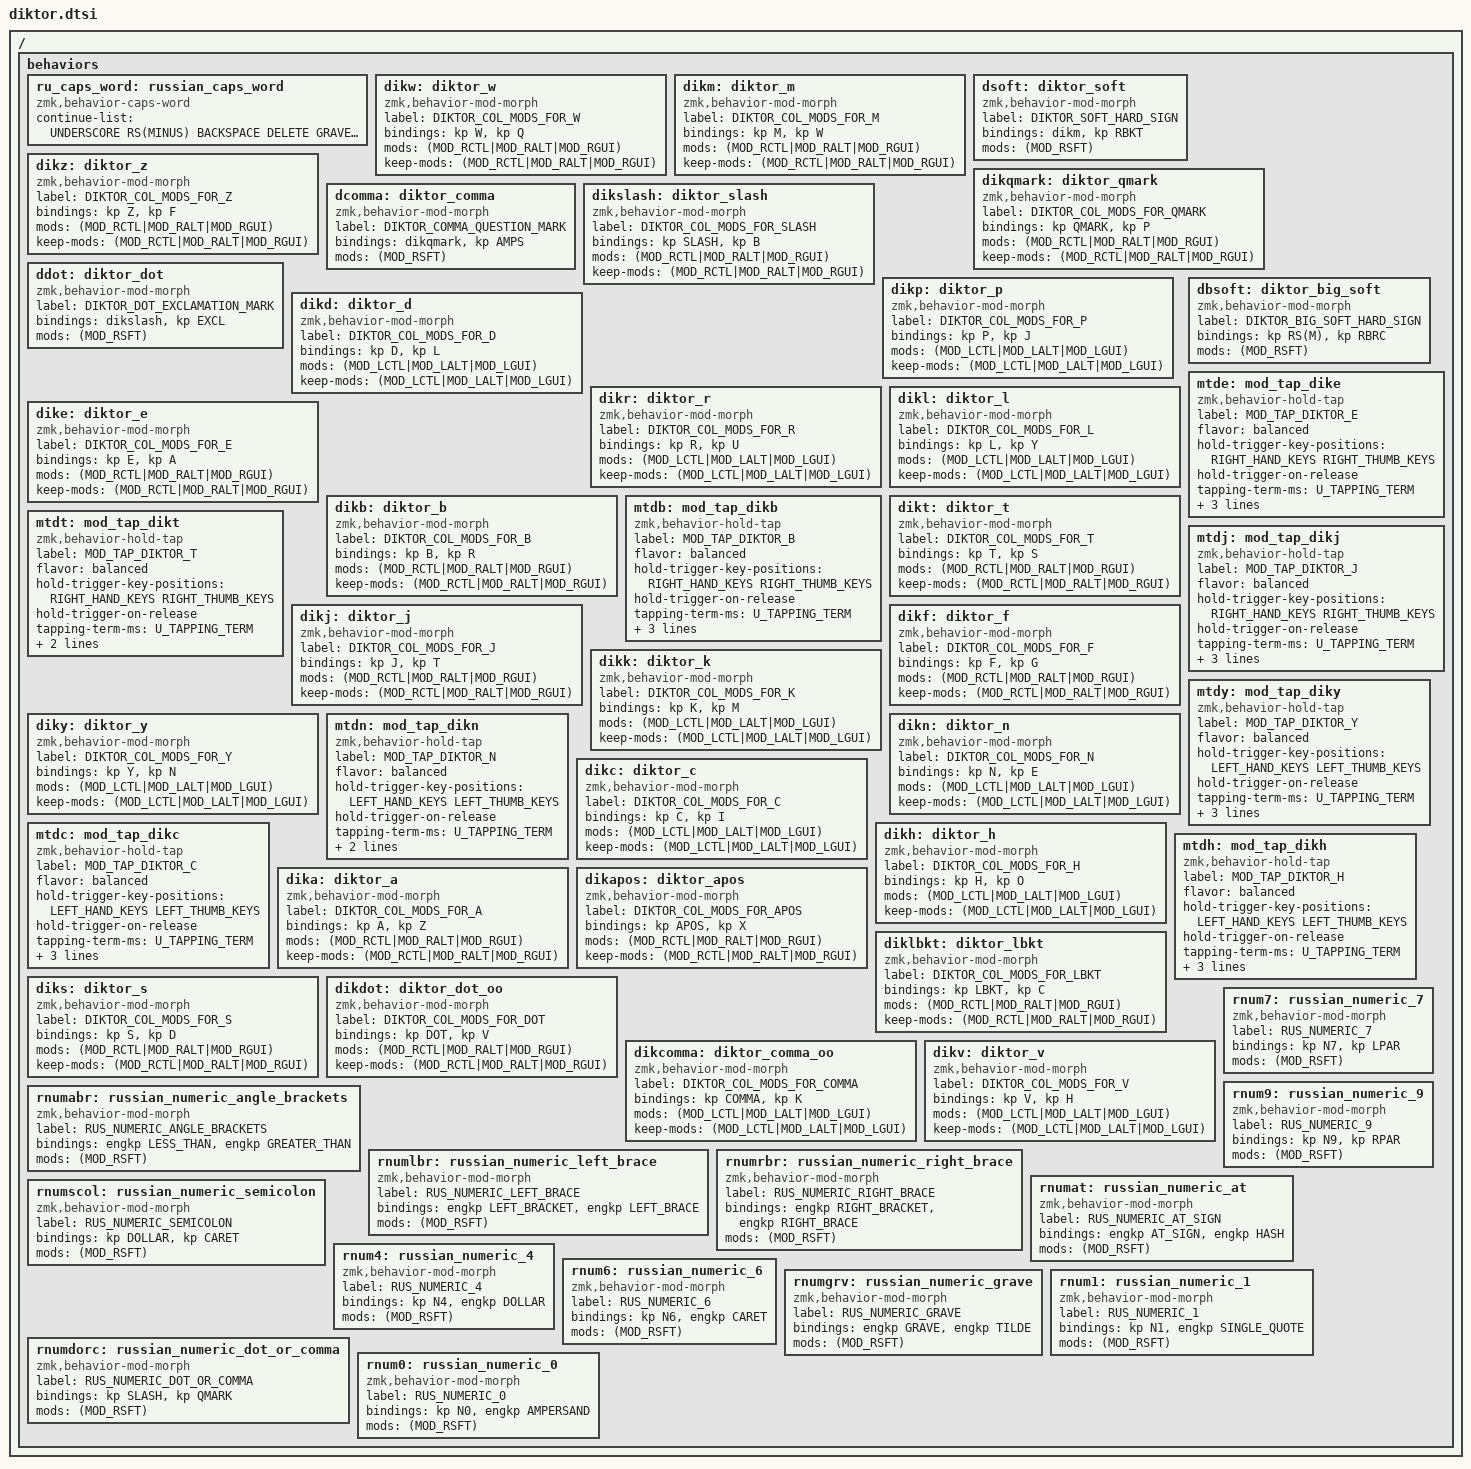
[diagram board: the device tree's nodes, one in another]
// Diktor layout behaviors

/ {
    behaviors {
        // Russian layer
        ru_caps_word: russian_caps_word {
            // behavior-caps-word is useless for Russian as it doesn't shift chars outside of a-z
            // loking forward to PR#2043's &capslock_word
            compatible = "zmk,behavior-caps-word";
            #binding-cells = <0>;
            continue-list = <UNDERSCORE RS(MINUS) BACKSPACE DELETE GRAVE LBKT RBKT APOS DOT COMMA SEMI>;
        };
        //  Ц >> Q
        dikw: diktor_w {
            compatible = "zmk,behavior-mod-morph";
            label = "DIKTOR_COL_MODS_FOR_W";
            #binding-cells = <0>;
            bindings = <&kp W>, <&kp Q>;
            mods = <(MOD_RCTL|MOD_RALT|MOD_RGUI)>;
            keep-mods = <(MOD_RCTL|MOD_RALT|MOD_RGUI)>;
        };
        //  ь/ъ >> W
        dikm: diktor_m {
            compatible = "zmk,behavior-mod-morph";
            label = "DIKTOR_COL_MODS_FOR_M";
            #binding-cells = <0>;
            bindings = <&kp M>, <&kp W>;
            mods = <(MOD_RCTL|MOD_RALT|MOD_RGUI)>;
            keep-mods = <(MOD_RCTL|MOD_RALT|MOD_RGUI)>;
        };
        dsoft: diktor_soft {
            compatible = "zmk,behavior-mod-morph";
            label = "DIKTOR_SOFT_HARD_SIGN";
            #binding-cells = <0>;
            bindings = <&dikm>, <&kp RBKT>;
            mods = <(MOD_RSFT)>;
        };
        //  Я >> F
        dikz: diktor_z {
            compatible = "zmk,behavior-mod-morph";
            label = "DIKTOR_COL_MODS_FOR_Z";
            #binding-cells = <0>;
            bindings = <&kp Z>, <&kp F>;
            mods = <(MOD_RCTL|MOD_RALT|MOD_RGUI)>;
            keep-mods = <(MOD_RCTL|MOD_RALT|MOD_RGUI)>;
        };
        //  ,/? >> P
        dikqmark: diktor_qmark {
            compatible = "zmk,behavior-mod-morph";
            label = "DIKTOR_COL_MODS_FOR_QMARK";
            #binding-cells = <0>;
            bindings = <&kp QMARK>, <&kp P>;
            mods = <(MOD_RCTL|MOD_RALT|MOD_RGUI)>;
            keep-mods = <(MOD_RCTL|MOD_RALT|MOD_RGUI)>;
        };
        dcomma: diktor_comma {
            compatible = "zmk,behavior-mod-morph";
            label = "DIKTOR_COMMA_QUESTION_MARK";
            #binding-cells = <0>;
            bindings = <&dikqmark>, <&kp AMPS>;
            mods = <(MOD_RSFT)>;
        };
        //  ./! >> B
        dikslash: diktor_slash {
            compatible = "zmk,behavior-mod-morph";
            label = "DIKTOR_COL_MODS_FOR_SLASH";
            #binding-cells = <0>;
            bindings = <&kp SLASH>, <&kp B>;
            mods = <(MOD_RCTL|MOD_RALT|MOD_RGUI)>;
            keep-mods = <(MOD_RCTL|MOD_RALT|MOD_RGUI)>;
        };
        ddot: diktor_dot {
            compatible = "zmk,behavior-mod-morph";
            label = "DIKTOR_DOT_EXCLAMATION_MARK";
            #binding-cells = <0>;
            bindings = <&dikslash>, <&kp EXCL>;
            mods = <(MOD_RSFT)>;
        };
        //  З >> J
        dikp: diktor_p {
            compatible = "zmk,behavior-mod-morph";
            label = "DIKTOR_COL_MODS_FOR_P";
            #binding-cells = <0>;
            bindings = <&kp P>, <&kp J>;
            mods = <(MOD_LCTL|MOD_LALT|MOD_LGUI)>;
            keep-mods = <(MOD_LCTL|MOD_LALT|MOD_LGUI)>;
        };
        //  В >> L
        dikd: diktor_d {
            compatible = "zmk,behavior-mod-morph";
            label = "DIKTOR_COL_MODS_FOR_D";
            #binding-cells = <0>;
            bindings = <&kp D>, <&kp L>;
            mods = <(MOD_LCTL|MOD_LALT|MOD_LGUI)>;
            keep-mods = <(MOD_LCTL|MOD_LALT|MOD_LGUI)>;
        };
        //  К >> U
        dikr: diktor_r {
            compatible = "zmk,behavior-mod-morph";
            label = "DIKTOR_COL_MODS_FOR_R";
            #binding-cells = <0>;
            bindings = <&kp R>, <&kp U>;
            mods = <(MOD_LCTL|MOD_LALT|MOD_LGUI)>;
            keep-mods = <(MOD_LCTL|MOD_LALT|MOD_LGUI)>;
        };
        //  Д >> Y
        dikl: diktor_l {
            compatible = "zmk,behavior-mod-morph";
            label = "DIKTOR_COL_MODS_FOR_L";
            #binding-cells = <0>;
            bindings = <&kp L>, <&kp Y>;
            mods = <(MOD_LCTL|MOD_LALT|MOD_LGUI)>;
            keep-mods = <(MOD_LCTL|MOD_LALT|MOD_LGUI)>;
        };
        //  Ь/Ъ
        dbsoft: diktor_big_soft {
            compatible = "zmk,behavior-mod-morph";
            label = "DIKTOR_BIG_SOFT_HARD_SIGN";
            #binding-cells = <0>;
            bindings = <&kp RS(M)>, <&kp RBRC>;
            mods = <(MOD_RSFT)>;
        };
        //  У >> A
        dike: diktor_e {
            compatible = "zmk,behavior-mod-morph";
            label = "DIKTOR_COL_MODS_FOR_E";
            #binding-cells = <0>;
            bindings = <&kp E>, <&kp A>;
            mods = <(MOD_RCTL|MOD_RALT|MOD_RGUI)>;
            keep-mods = <(MOD_RCTL|MOD_RALT|MOD_RGUI)>;
        };
        mtde: mod_tap_dike {
            compatible = "zmk,behavior-hold-tap";
            label = "MOD_TAP_DIKTOR_E";
            flavor = "balanced";
            hold-trigger-key-positions = <RIGHT_HAND_KEYS RIGHT_THUMB_KEYS>;
            hold-trigger-on-release; // for combining HRMs
            tapping-term-ms = <U_TAPPING_TERM>;
            quick-tap-ms = <U_QUICK_TAP>;
            require-prior-idle-ms = <U_STREAK_DECAY>;
            #binding-cells = <2>;
            bindings = <&kp>, <&dike>;
        };
        //  И >> R
        dikb: diktor_b {
            compatible = "zmk,behavior-mod-morph";
            label = "DIKTOR_COL_MODS_FOR_B";
            #binding-cells = <0>;
            bindings = <&kp B>, <&kp R>;
            mods = <(MOD_RCTL|MOD_RALT|MOD_RGUI)>;
            keep-mods = <(MOD_RCTL|MOD_RALT|MOD_RGUI)>;
        };
        mtdb: mod_tap_dikb {
            compatible = "zmk,behavior-hold-tap";
            label = "MOD_TAP_DIKTOR_B";
            flavor = "balanced";
            hold-trigger-key-positions = <RIGHT_HAND_KEYS RIGHT_THUMB_KEYS>;
            hold-trigger-on-release; // for combining HRMs
            tapping-term-ms = <U_TAPPING_TERM>;
            quick-tap-ms = <U_QUICK_TAP>;
            require-prior-idle-ms = <U_STREAK_DECAY>;
            #binding-cells = <2>;
            bindings = <&kp>, <&dikb>;
        };
        //  Е >> S
        dikt: diktor_t {
            compatible = "zmk,behavior-mod-morph";
            label = "DIKTOR_COL_MODS_FOR_T";
            #binding-cells = <0>;
            bindings = <&kp T>, <&kp S>;
            mods = <(MOD_RCTL|MOD_RALT|MOD_RGUI)>;
            keep-mods = <(MOD_RCTL|MOD_RALT|MOD_RGUI)>;
        };
        mtdt: mod_tap_dikt {
            compatible = "zmk,behavior-hold-tap";
            label = "MOD_TAP_DIKTOR_T";
            flavor = "balanced";
            hold-trigger-key-positions = <RIGHT_HAND_KEYS RIGHT_THUMB_KEYS>;
            hold-trigger-on-release; // for combining HRMs
            tapping-term-ms = <U_TAPPING_TERM>;
            quick-tap-ms = <U_QUICK_TAP>;
            #binding-cells = <2>;
            bindings = <&kp>, <&dikt>;
        };
        //  О >> T
        dikj: diktor_j {
            compatible = "zmk,behavior-mod-morph";
            label = "DIKTOR_COL_MODS_FOR_J";
            #binding-cells = <0>;
            bindings = <&kp J>, <&kp T>;
            mods = <(MOD_RCTL|MOD_RALT|MOD_RGUI)>;
            keep-mods = <(MOD_RCTL|MOD_RALT|MOD_RGUI)>;
        };
        mtdj: mod_tap_dikj {
            compatible = "zmk,behavior-hold-tap";
            label = "MOD_TAP_DIKTOR_J";
            flavor = "balanced";
            hold-trigger-key-positions = <RIGHT_HAND_KEYS RIGHT_THUMB_KEYS>;
            hold-trigger-on-release; // for combining HRMs
            tapping-term-ms = <U_TAPPING_TERM>;
            quick-tap-ms = <U_QUICK_TAP>;
            require-prior-idle-ms = <U_STREAK_DECAY>;
            #binding-cells = <2>;
            bindings = <&kp>, <&dikj>;
        };
        //  А >> G
        dikf: diktor_f {
            compatible = "zmk,behavior-mod-morph";
            label = "DIKTOR_COL_MODS_FOR_F";
            #binding-cells = <0>;
            bindings = <&kp F>, <&kp G>;
            mods = <(MOD_RCTL|MOD_RALT|MOD_RGUI)>;
            keep-mods = <(MOD_RCTL|MOD_RALT|MOD_RGUI)>;
        };
        //  Л >> M
        dikk: diktor_k {
            compatible = "zmk,behavior-mod-morph";
            label = "DIKTOR_COL_MODS_FOR_K";
            #binding-cells = <0>;
            bindings = <&kp K>, <&kp M>;
            mods = <(MOD_LCTL|MOD_LALT|MOD_LGUI)>;
            keep-mods = <(MOD_LCTL|MOD_LALT|MOD_LGUI)>;
        };
        //  Н >> N
        diky: diktor_y {
            compatible = "zmk,behavior-mod-morph";
            label = "DIKTOR_COL_MODS_FOR_Y";
            #binding-cells = <0>;
            bindings = <&kp Y>, <&kp N>;
            mods = <(MOD_LCTL|MOD_LALT|MOD_LGUI)>;
            keep-mods = <(MOD_LCTL|MOD_LALT|MOD_LGUI)>;
        };
        mtdy: mod_tap_diky {
            compatible = "zmk,behavior-hold-tap";
            label = "MOD_TAP_DIKTOR_Y";
            flavor = "balanced";
            hold-trigger-key-positions = <LEFT_HAND_KEYS LEFT_THUMB_KEYS>;
            hold-trigger-on-release; // for combining HRMs
            tapping-term-ms = <U_TAPPING_TERM>;
            quick-tap-ms = <U_QUICK_TAP>;
            require-prior-idle-ms = <U_STREAK_DECAY>;
            #binding-cells = <2>;
            bindings = <&kp>, <&diky>;
        };
        //  Т >> E
        dikn: diktor_n {
            compatible = "zmk,behavior-mod-morph";
            label = "DIKTOR_COL_MODS_FOR_N";
            #binding-cells = <0>;
            bindings = <&kp N>, <&kp E>;
            mods = <(MOD_LCTL|MOD_LALT|MOD_LGUI)>;
            keep-mods = <(MOD_LCTL|MOD_LALT|MOD_LGUI)>;
        };
        mtdn: mod_tap_dikn {
            compatible = "zmk,behavior-hold-tap";
            label = "MOD_TAP_DIKTOR_N";
            flavor = "balanced";
            hold-trigger-key-positions = <LEFT_HAND_KEYS LEFT_THUMB_KEYS>;
            hold-trigger-on-release; // for combining HRMs
            tapping-term-ms = <U_TAPPING_TERM>;
            quick-tap-ms = <U_QUICK_TAP>;
            #binding-cells = <2>;
            bindings = <&kp>, <&dikn>;
        };
        //  С >> I
        dikc: diktor_c {
            compatible = "zmk,behavior-mod-morph";
            label = "DIKTOR_COL_MODS_FOR_C";
            #binding-cells = <0>;
            bindings = <&kp C>, <&kp I>;
            mods = <(MOD_LCTL|MOD_LALT|MOD_LGUI)>;
            keep-mods = <(MOD_LCTL|MOD_LALT|MOD_LGUI)>;
        };
        mtdc: mod_tap_dikc {
            compatible = "zmk,behavior-hold-tap";
            label = "MOD_TAP_DIKTOR_C";
            flavor = "balanced";
            hold-trigger-key-positions = <LEFT_HAND_KEYS LEFT_THUMB_KEYS>;
            hold-trigger-on-release; // for combining HRMs
            tapping-term-ms = <U_TAPPING_TERM>;
            quick-tap-ms = <U_QUICK_TAP>;
            require-prior-idle-ms = <U_STREAK_DECAY>;
            #binding-cells = <2>;
            bindings = <&kp>, <&dikc>;
        };
        //  Р >> O
        dikh: diktor_h {
            compatible = "zmk,behavior-mod-morph";
            label = "DIKTOR_COL_MODS_FOR_H";
            #binding-cells = <0>;
            bindings = <&kp H>, <&kp O>;
            mods = <(MOD_LCTL|MOD_LALT|MOD_LGUI)>;
            keep-mods = <(MOD_LCTL|MOD_LALT|MOD_LGUI)>;
        };
        mtdh: mod_tap_dikh {
            compatible = "zmk,behavior-hold-tap";
            label = "MOD_TAP_DIKTOR_H";
            flavor = "balanced";
            hold-trigger-key-positions = <LEFT_HAND_KEYS LEFT_THUMB_KEYS>;
            hold-trigger-on-release; // for combining HRMs
            tapping-term-ms = <U_TAPPING_TERM>;
            quick-tap-ms = <U_QUICK_TAP>;
            require-prior-idle-ms = <U_STREAK_DECAY>;
            #binding-cells = <2>;
            bindings = <&kp>, <&dikh>;
        };
        //  Ф >> Z
        dika: diktor_a {
            compatible = "zmk,behavior-mod-morph";
            label = "DIKTOR_COL_MODS_FOR_A";
            #binding-cells = <0>;
            bindings = <&kp A>, <&kp Z>;
            mods = <(MOD_RCTL|MOD_RALT|MOD_RGUI)>;
            keep-mods = <(MOD_RCTL|MOD_RALT|MOD_RGUI)>;
        };
        //  Э >> X
        dikapos: diktor_apos {
            compatible = "zmk,behavior-mod-morph";
            label = "DIKTOR_COL_MODS_FOR_APOS";
            #binding-cells = <0>;
            bindings = <&kp APOS>, <&kp X>;
            mods = <(MOD_RCTL|MOD_RALT|MOD_RGUI)>;
            keep-mods = <(MOD_RCTL|MOD_RALT|MOD_RGUI)>;
        };
        //  Х >> C
        diklbkt: diktor_lbkt {
            compatible = "zmk,behavior-mod-morph";
            label = "DIKTOR_COL_MODS_FOR_LBKT";
            #binding-cells = <0>;
            bindings = <&kp LBKT>, <&kp C>;
            mods = <(MOD_RCTL|MOD_RALT|MOD_RGUI)>;
            keep-mods = <(MOD_RCTL|MOD_RALT|MOD_RGUI)>;
        };
        //  Ы >> D
        diks: diktor_s {
            compatible = "zmk,behavior-mod-morph";
            label = "DIKTOR_COL_MODS_FOR_S";
            #binding-cells = <0>;
            bindings = <&kp S>, <&kp D>;
            mods = <(MOD_RCTL|MOD_RALT|MOD_RGUI)>;
            keep-mods = <(MOD_RCTL|MOD_RALT|MOD_RGUI)>;
        };
        //  Ю >> V
        dikdot: diktor_dot_oo {
            compatible = "zmk,behavior-mod-morph";
            label = "DIKTOR_COL_MODS_FOR_DOT";
            #binding-cells = <0>;
            bindings = <&kp DOT>, <&kp V>;
            mods = <(MOD_RCTL|MOD_RALT|MOD_RGUI)>;
            keep-mods = <(MOD_RCTL|MOD_RALT|MOD_RGUI)>;
        };
        //  Б >> K
        dikcomma: diktor_comma_oo {
            compatible = "zmk,behavior-mod-morph";
            label = "DIKTOR_COL_MODS_FOR_COMMA";
            #binding-cells = <0>;
            bindings = <&kp COMMA>, <&kp K>;
            mods = <(MOD_LCTL|MOD_LALT|MOD_LGUI)>;
            keep-mods = <(MOD_LCTL|MOD_LALT|MOD_LGUI)>;
        };
        //  М >> H
        dikv: diktor_v {
            compatible = "zmk,behavior-mod-morph";
            label = "DIKTOR_COL_MODS_FOR_V";
            #binding-cells = <0>;
            bindings = <&kp V>, <&kp H>;
            mods = <(MOD_LCTL|MOD_LALT|MOD_LGUI)>;
            keep-mods = <(MOD_LCTL|MOD_LALT|MOD_LGUI)>;
        };

        // Russian Number layer
        rnumabr: russian_numeric_angle_brackets {
            compatible = "zmk,behavior-mod-morph";
            label = "RUS_NUMERIC_ANGLE_BRACKETS";
            #binding-cells = <0>;
            bindings = <&engkp LESS_THAN>, <&engkp GREATER_THAN>;
            mods = <(MOD_RSFT)>;
        };
        rnumlbr: russian_numeric_left_brace {
            compatible = "zmk,behavior-mod-morph";
            label = "RUS_NUMERIC_LEFT_BRACE";
            #binding-cells = <0>;
            bindings = <&engkp LEFT_BRACKET>, <&engkp LEFT_BRACE>;
            mods = <(MOD_RSFT)>;
        };
        rnum7: russian_numeric_7 {
            compatible = "zmk,behavior-mod-morph";
            label = "RUS_NUMERIC_7";
            #binding-cells = <0>;
            bindings = <&kp N7>, <&kp LPAR>;
            mods = <(MOD_RSFT)>;
        };
        rnum9: russian_numeric_9 {
            compatible = "zmk,behavior-mod-morph";
            label = "RUS_NUMERIC_9";
            #binding-cells = <0>;
            bindings = <&kp N9>, <&kp RPAR>;
            mods = <(MOD_RSFT)>;
        };
        rnumrbr: russian_numeric_right_brace {
            compatible = "zmk,behavior-mod-morph";
            label = "RUS_NUMERIC_RIGHT_BRACE";
            #binding-cells = <0>;
            bindings = <&engkp RIGHT_BRACKET>, <&engkp RIGHT_BRACE>;
            mods = <(MOD_RSFT)>;
        };
        rnumat: russian_numeric_at {
            compatible = "zmk,behavior-mod-morph";
            label = "RUS_NUMERIC_AT_SIGN";
            #binding-cells = <0>;
            bindings = <&engkp AT_SIGN>, <&engkp HASH>;
            mods = <(MOD_RSFT)>;
        };
        rnumscol: russian_numeric_semicolon {
            compatible = "zmk,behavior-mod-morph";
            label = "RUS_NUMERIC_SEMICOLON";
            #binding-cells = <0>;
            bindings = <&kp DOLLAR>, <&kp CARET>;
            mods = <(MOD_RSFT)>;
        };
        rnum4: russian_numeric_4 {
            compatible = "zmk,behavior-mod-morph";
            label = "RUS_NUMERIC_4";
            #binding-cells = <0>;
            bindings = <&kp N4>, <&engkp DOLLAR>;
            mods = <(MOD_RSFT)>;
        };
        rnum6: russian_numeric_6 {
            compatible = "zmk,behavior-mod-morph";
            label = "RUS_NUMERIC_6";
            #binding-cells = <0>;
            bindings = <&kp N6>, <&engkp CARET>;
            mods = <(MOD_RSFT)>;
        };
        rnumgrv: russian_numeric_grave {
            compatible = "zmk,behavior-mod-morph";
            label = "RUS_NUMERIC_GRAVE";
            #binding-cells = <0>;
            bindings = <&engkp GRAVE>, <&engkp TILDE>;
            mods = <(MOD_RSFT)>;
        };
        rnum1: russian_numeric_1 {
            compatible = "zmk,behavior-mod-morph";
            label = "RUS_NUMERIC_1";
            #binding-cells = <0>;
            bindings = <&kp N1>, <&engkp SINGLE_QUOTE>;
            mods = <(MOD_RSFT)>;
        };
        //  ./,
        rnumdorc: russian_numeric_dot_or_comma {
            compatible = "zmk,behavior-mod-morph";
            label = "RUS_NUMERIC_DOT_OR_COMMA";
            #binding-cells = <0>;
            bindings = <&kp SLASH>, <&kp QMARK>;
            mods = <(MOD_RSFT)>;
        };
        rnum0: russian_numeric_0 {
            compatible = "zmk,behavior-mod-morph";
            label = "RUS_NUMERIC_0";
            #binding-cells = <0>;
            bindings = <&kp N0>, <&engkp AMPERSAND>;
            mods = <(MOD_RSFT)>;
        };
    };
};
